# N32G030 register map
Vendor: Nationstech Ltd.; File version: 1.0
Registers are 32-bit, read-write, reset 0x0 unless marked. A register's access mark holds for its fields unless they carry their own. Offsets are from the block's base; [hi:lo] are bit positions; {n}, {i} and the like mark numbered series.

## AFIO — Alternate function I/O
Base 0x40010000
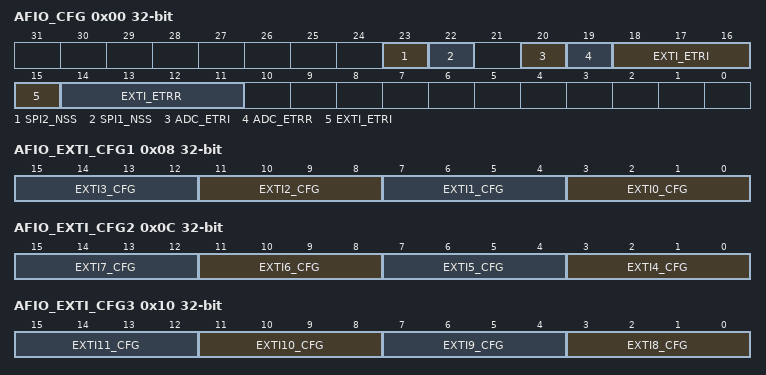
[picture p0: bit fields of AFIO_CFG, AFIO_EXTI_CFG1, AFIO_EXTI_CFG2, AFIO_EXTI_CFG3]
0x00 AFIO_CFG
  [23] SPI2_NSS, [22] SPI1_NSS, [20] ADC_ETRI, [19] ADC_ETRR, [18:15] EXTI_ETRI, [14:11] EXTI_ETRR
0x08 AFIO_EXTI_CFG1
  [4n+3:4n] EXTI{n}_CFG (n=0..3)
0x0C AFIO_EXTI_CFG2
  [4n-13:4n-16] EXTI{n}_CFG (n=4..7)
0x10 AFIO_EXTI_CFG3
  [4n-29:4n-32] EXTI{n}_CFG (n=8..11)
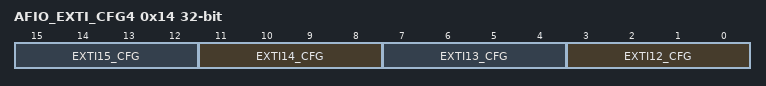
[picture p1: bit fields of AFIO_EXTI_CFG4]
0x14 AFIO_EXTI_CFG4
  [4n-45:4n-48] EXTI{n}_CFG (n=12..15)

## HDIV — High-speed divider
Base 0x40028000
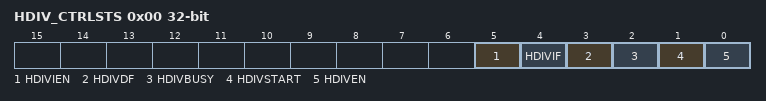
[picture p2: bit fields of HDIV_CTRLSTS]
0x00 HDIV_CTRLSTS
  [5] HDIVIEN, [4] HDIVIF, [3] HDIVDF, [2] HDIVBUSY, [1] HDIVSTART, [0] HDIVEN
0x04 HDIV_DIVIDEND
0x08 HDIV_DIVISOR
0x0C HDIV_QUOTIENT
0x10 HDIV_REMAINDER
0x14 HDIV_DIVBY0
  [0] DIVBY0

## I2C1 — Inter integrated circuit
Base 0x40005400
Same registers: I2C2 0x40005800
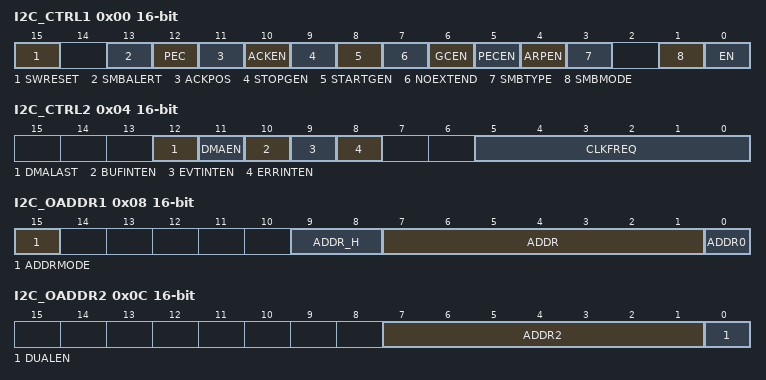
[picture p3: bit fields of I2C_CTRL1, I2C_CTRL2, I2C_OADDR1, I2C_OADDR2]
0x00 I2C_CTRL1 16-bit
  [15] SWRESET, [13] SMBALERT, [12] PEC, [11] ACKPOS, [10] ACKEN, [9] STOPGEN, [8] STARTGEN, [7] NOEXTEND, [6] GCEN, [5] PECEN, [4] ARPEN, [3] SMBTYPE, [1] SMBMODE, [0] EN
0x04 I2C_CTRL2 16-bit
  [12] DMALAST, [11] DMAEN, [10] BUFINTEN, [9] EVTINTEN, [8] ERRINTEN, [5:0] CLKFREQ
0x08 I2C_OADDR1 16-bit
  [15] ADDRMODE, [9:8] ADDR_H, [7:1] ADDR, [0] ADDR0
0x0C I2C_OADDR2 16-bit
  [7:1] ADDR2, [0] DUALEN
0x10 I2C_DAT 16-bit
  [7:0] DATA
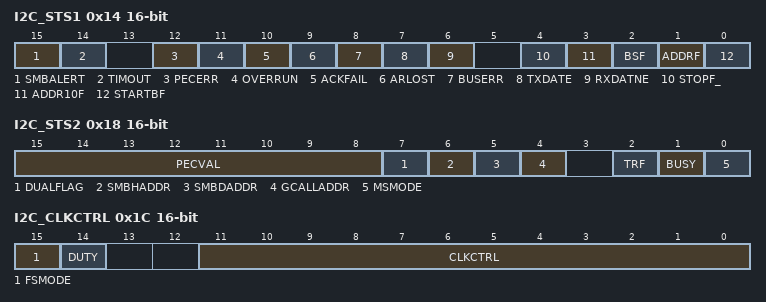
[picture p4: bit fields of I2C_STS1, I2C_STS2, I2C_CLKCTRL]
0x14 I2C_STS1 16-bit
  [15] SMBALERT, [14] TIMOUT, [12] PECERR, [11] OVERRUN, [10] ACKFAIL, [9] ARLOST, [8] BUSERR, [7] TXDATE, [6] RXDATNE, [4] STOPF_, [3] ADDR10F, [2] BSF, [1] ADDRF, [0] STARTBF
0x18 I2C_STS2 16-bit
  [15:8] PECVAL, [7] DUALFLAG, [6] SMBHADDR, [5] SMBDADDR, [4] GCALLADDR, [2] TRF, [1] BUSY, [0] MSMODE
0x1C I2C_CLKCTRL 16-bit
  [15] FSMODE, [14] DUTY, [11:0] CLKCTRL
0x20 I2C_TMRISE 16-bit
  [5:0] TMRISE

## IWDG — Independent watchdog
Base 0x40003000
0x00 IWDG_KEY
  [15:0] KEYV
0x04 IWDG_PREDIV
  [2:0] PD
0x08 IWDG_RELV reset 0xFFF
  [11:0] REL
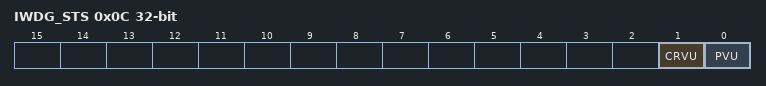
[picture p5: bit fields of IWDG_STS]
0x0C IWDG_STS
  [1] CRVU, [0] PVU

## LPTIM — Low power timer control
Base 0x40000C00
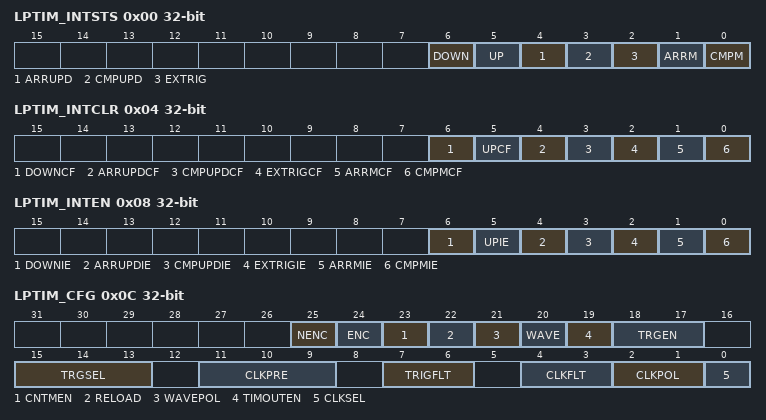
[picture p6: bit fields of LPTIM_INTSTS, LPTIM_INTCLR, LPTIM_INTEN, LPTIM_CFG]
0x00 LPTIM_INTSTS read
  [6] DOWN, [5] UP, [4] ARRUPD, [3] CMPUPD, [2] EXTRIG, [1] ARRM, [0] CMPM
0x04 LPTIM_INTCLR write
  [6] DOWNCF, [5] UPCF, [4] ARRUPDCF, [3] CMPUPDCF, [2] EXTRIGCF, [1] ARRMCF, [0] CMPMCF
0x08 LPTIM_INTEN
  [6] DOWNIE, [5] UPIE, [4] ARRUPDIE, [3] CMPUPDIE, [2] EXTRIGIE, [1] ARRMIE, [0] CMPMIE
0x0C LPTIM_CFG (reset mask 0x3FEEEEF)
  [25] NENC, [24] ENC, [23] CNTMEN, [22] RELOAD, [21] WAVEPOL, [20] WAVE, [19] TIMOUTEN, [18:17] TRGEN, [15:13] TRGSEL, [11:9] CLKPRE, [7:6] TRIGFLT, [4:3] CLKFLT, [2:1] CLKPOL, [0] CLKSEL
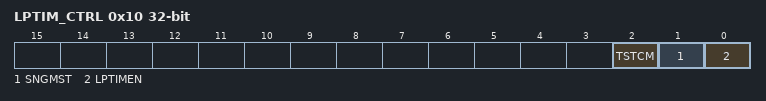
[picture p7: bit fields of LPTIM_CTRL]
0x10 LPTIM_CTRL
  [2] TSTCM, [1] SNGMST, [0] LPTIMEN
0x14 LPTIM_CMP
  [15:0] CMPVAL
0x18 LPTIM_ARR reset 0x1
  [15:0] ARRVAL
0x1C LPTIM_CNT reset 0x1
  [15:0] CNTVAL

## LPUART — Low-power universal asynchronous receiver transmitter
Base 0x40004800
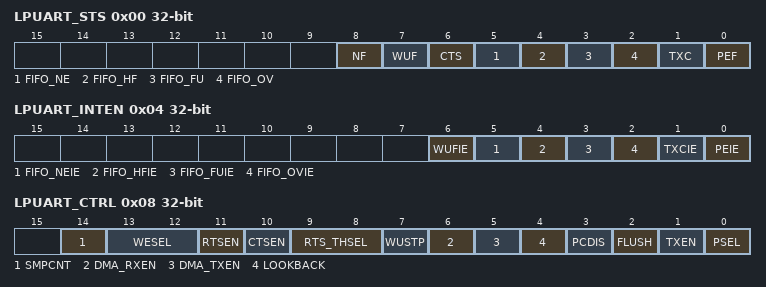
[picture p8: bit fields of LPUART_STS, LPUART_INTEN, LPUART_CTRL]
0x00 LPUART_STS
  [8] NF, [7] WUF, [6] CTS, [5] FIFO_NE, [4] FIFO_HF, [3] FIFO_FU, [2] FIFO_OV, [1] TXC, [0] PEF
0x04 LPUART_INTEN
  [6] WUFIE, [5] FIFO_NEIE, [4] FIFO_HFIE, [3] FIFO_FUIE, [2] FIFO_OVIE, [1] TXCIE, [0] PEIE
0x08 LPUART_CTRL
  [14] SMPCNT, [13:12] WESEL, [11] RTSEN, [10] CTSEN, [9:8] RTS_THSEL, [7] WUSTP, [6] DMA_RXEN, [5] DMA_TXEN, [4] LOOKBACK, [3] PCDIS, [2] FLUSH, [1] TXEN, [0] PSEL
0x0C LPUART_BRCFG1 reset 0x174
  [15:0] INTEGER
0x10 LPUART_DAT
  [7:0] DAT
0x14 LPUART_BRCFG2
  [7:0] DECIMAL
0x18 LPUART_WUDAT

## OPAMP — operational amplifier
Base 0x40002000
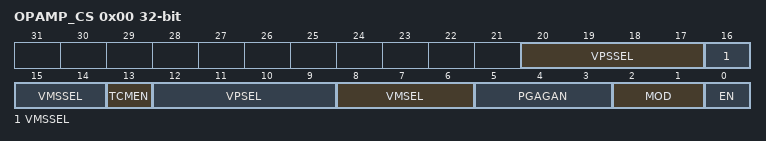
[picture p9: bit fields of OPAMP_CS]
0x00 OPAMP_CS
  [20:17] VPSSEL, [16:14] VMSSEL, [13] TCMEN, [12:9] VPSEL, [8:6] VMSEL, [5:3] PGAGAN, [2:1] MOD, [0] EN
0x04 OPAMP_LOCK
  [0] OPAMPLK

## PWR — Power control
Base 0x40007000
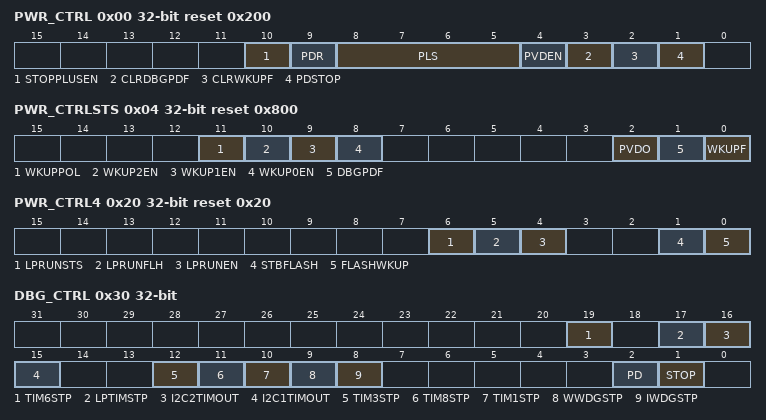
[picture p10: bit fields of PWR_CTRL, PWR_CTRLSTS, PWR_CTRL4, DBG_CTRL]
0x00 PWR_CTRL reset 0x200
  [10] STOPPLUSEN, [9] PDR, [8:5] PLS, [4] PVDEN, [3] CLRDBGPDF, [2] CLRWKUPF, [1] PDSTOP
0x04 PWR_CTRLSTS reset 0x800
  [11] WKUPPOL, [10] WKUP2EN, [9] WKUP1EN, [8] WKUP0EN, [2] PVDO, [1] DBGPDF, [0] WKUPF
0x08 PWR_CTRL2 reset 0x400
  [10] IWDGRSTEN
0x0C PWR_CTRL3 reset 0x37F
  [7] LSIEN
0x20 PWR_CTRL4 reset 0x20
  [6] LPRUNSTS, [5] LPRUNFLH, [4] LPRUNEN, [1] STBFLASH, [0] FLASHWKUP
0x24 PWR_CTRL5 reset 0x7 (reset mask 0xC0)
  [3:2] SLPMRSEL
0x28 PWR_CTRL6 (reset mask 0xC0)
  [3:2] STPMREN
0x30 DBG_CTRL (reset mask 0x79F06)
  [19] TIM6STP, [17] LPTIMSTP, [16] I2C2TIMOUT, [15] I2C1TIMOUT, [12] TIM3STP, [11] TIM8STP, [10] TIM1STP, [9] WWDGSTP, [8] IWDGSTP, [2] PD, [1] STOP
